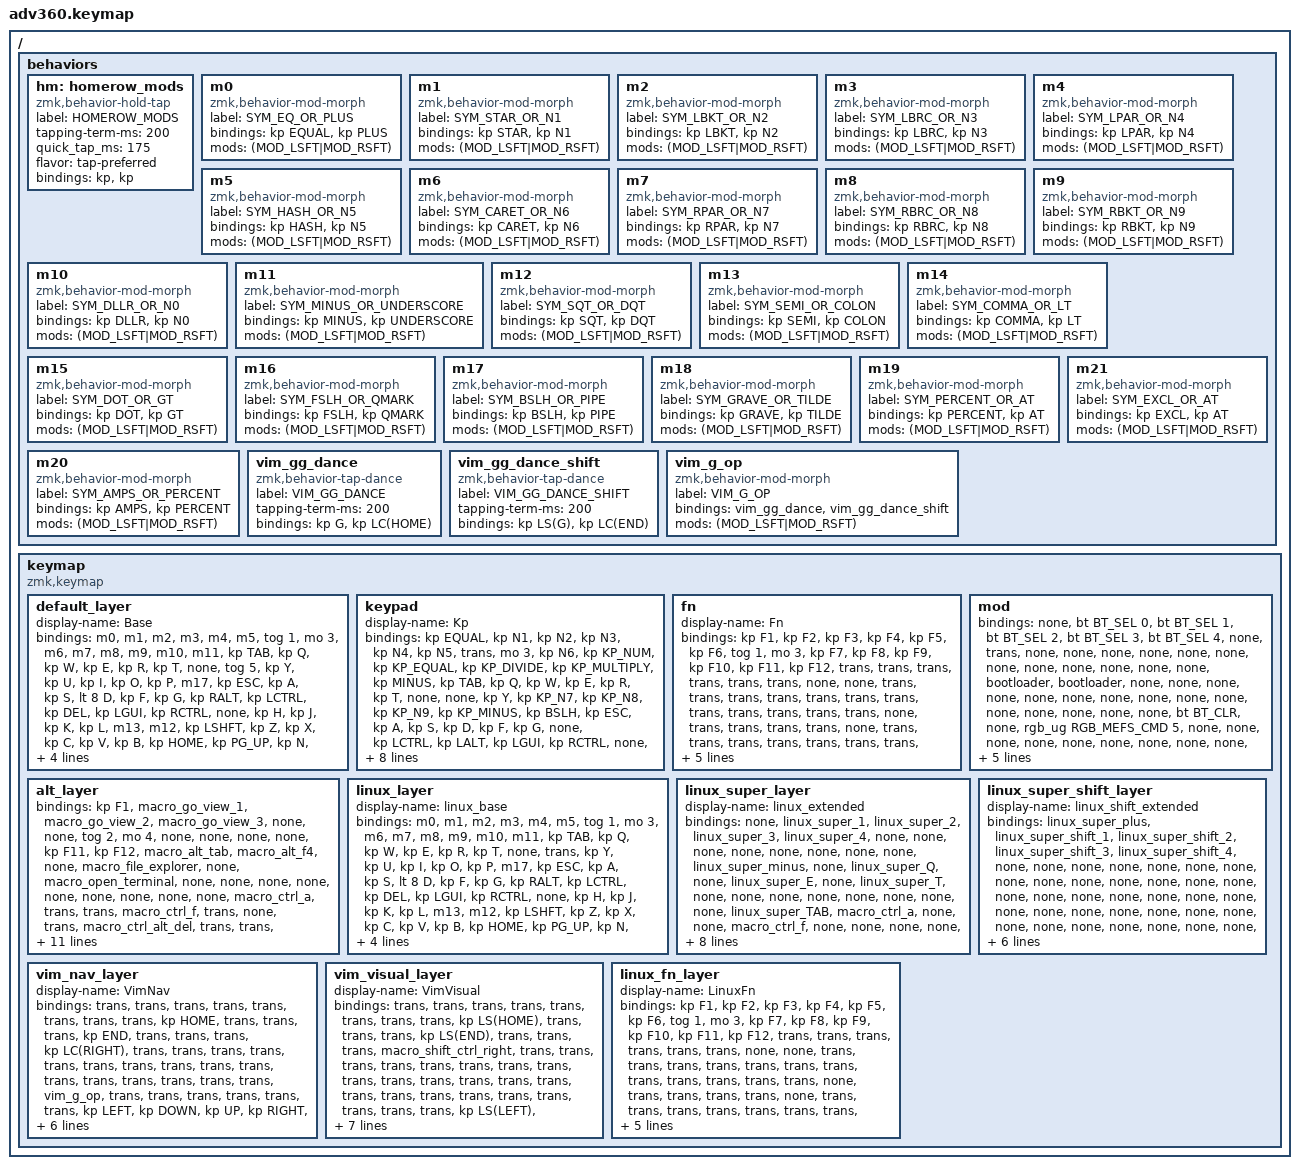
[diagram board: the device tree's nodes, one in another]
#include <behaviors.dtsi>
#include <dt-bindings/zmk/keys.h>
#include <dt-bindings/zmk/bt.h>
#include <dt-bindings/zmk/rgb.h>
#include <dt-bindings/zmk/stp.h>
#include <dt-bindings/zmk/backlight.h>
#include <dt-bindings/zmk/pointing.h>

/ {
    behaviors {
      #include "macros.dtsi"
      #include "version.dtsi"

      hm: homerow_mods {
          compatible = "zmk,behavior-hold-tap";
          label = "HOMEROW_MODS";
          #binding-cells = <2>;
          tapping-term-ms = <200>;
          quick_tap_ms = <175>;
          flavor = "tap-preferred";
          bindings = <&kp>, <&kp>;
      };

      m0: m0 {
          compatible = "zmk,behavior-mod-morph";
          label = "SYM_EQ_OR_PLUS";
          #binding-cells = <0>;
          bindings = <&kp EQUAL>, <&kp PLUS>;  // = <> +
          mods = <(MOD_LSFT|MOD_RSFT)>;
      };

      m1: m1 {
          compatible = "zmk,behavior-mod-morph";
          label = "SYM_STAR_OR_N1";
          #binding-cells = <0>;
          bindings = <&kp STAR>, <&kp N1>; // * <> 1
          mods = <(MOD_LSFT|MOD_RSFT)>;
      };

      m2: m2 {
          compatible = "zmk,behavior-mod-morph";
          label = "SYM_LBKT_OR_N2";
          #binding-cells = <0>;
          bindings = <&kp LBKT>, <&kp N2>; // [ <> 2
          mods = <(MOD_LSFT|MOD_RSFT)>;
      };

      m3: m3 {
          compatible = "zmk,behavior-mod-morph";
          label = "SYM_LBRC_OR_N3";
          #binding-cells = <0>;
          bindings = <&kp LBRC>, <&kp N3>; // { <> 3
          mods = <(MOD_LSFT|MOD_RSFT)>;
      };

      m4: m4 {
          compatible = "zmk,behavior-mod-morph";
          label = "SYM_LPAR_OR_N4";
          #binding-cells = <0>;
          bindings = <&kp LPAR>, <&kp N4>; // ( <> 4
          mods = <(MOD_LSFT|MOD_RSFT)>;
      };

      m5: m5 {
          compatible = "zmk,behavior-mod-morph";
          label = "SYM_HASH_OR_N5";
          #binding-cells = <0>;
          bindings = <&kp HASH>, <&kp N5>; // # <> 5
          mods = <(MOD_LSFT|MOD_RSFT)>;
      };

      m6: m6 {
          compatible = "zmk,behavior-mod-morph";
          label = "SYM_CARET_OR_N6";
          #binding-cells = <0>;
          bindings = <&kp CARET>, <&kp N6>; // ^ <> 6
          mods = <(MOD_LSFT|MOD_RSFT)>;
      };

      m7: m7 {
          compatible = "zmk,behavior-mod-morph";
          label = "SYM_RPAR_OR_N7";
          #binding-cells = <0>;
          bindings = <&kp RPAR>, <&kp N7>; // ) <> 7
          mods = <(MOD_LSFT|MOD_RSFT)>;
      };

      m8: m8 {
          compatible = "zmk,behavior-mod-morph";
          label = "SYM_RBRC_OR_N8";
          #binding-cells = <0>;
          bindings = <&kp RBRC>, <&kp N8>; // } <> 8
          mods = <(MOD_LSFT|MOD_RSFT)>;
      };

      m9: m9 {
          compatible = "zmk,behavior-mod-morph";
          label = "SYM_RBKT_OR_N9";
          #binding-cells = <0>;
          bindings = <&kp RBKT>, <&kp N9>; // ] <> 9
          mods = <(MOD_LSFT|MOD_RSFT)>;
      };

      m10: m10 {
          compatible = "zmk,behavior-mod-morph";
          label = "SYM_DLLR_OR_N0";
          #binding-cells = <0>;
          bindings = <&kp DLLR>, <&kp N0>; // $ <> 0
          mods = <(MOD_LSFT|MOD_RSFT)>;
      };

      m11: m11 {
          compatible = "zmk,behavior-mod-morph";
          label = "SYM_MINUS_OR_UNDERSCORE"; // - <> _
          #binding-cells = <0>;
          bindings = <&kp MINUS>, <&kp UNDERSCORE>;
          mods = <(MOD_LSFT|MOD_RSFT)>;
      };

      m12: m12 {
          compatible = "zmk,behavior-mod-morph";
          label = "SYM_SQT_OR_DQT"; // ' <> "
          #binding-cells = <0>;
          bindings = <&kp SQT>, <&kp DQT>;
          mods = <(MOD_LSFT|MOD_RSFT)>;
      };

      m13: m13 {
          compatible = "zmk,behavior-mod-morph";
          label = "SYM_SEMI_OR_COLON"; // ; <> :
          #binding-cells = <0>;
          bindings = <&kp SEMI>, <&kp COLON>;
          mods = <(MOD_LSFT|MOD_RSFT)>;
      };

      m14: m14 {
          compatible = "zmk,behavior-mod-morph";
          label = "SYM_COMMA_OR_LT"; // , <> <
              #binding-cells = <0>;
              bindings = <&kp COMMA>, <&kp LT>;
              mods = <(MOD_LSFT|MOD_RSFT)>;
      };

      m15: m15 {
          compatible = "zmk,behavior-mod-morph";
          label = "SYM_DOT_OR_GT"; // . <> >
          #binding-cells = <0>;
          bindings = <&kp DOT>, <&kp GT>;
          mods = <(MOD_LSFT|MOD_RSFT)>;
      };

      m16: m16 {
          compatible = "zmk,behavior-mod-morph";
          label = "SYM_FSLH_OR_QMARK"; // / <> ?
          #binding-cells = <0>;
          bindings = <&kp FSLH>, <&kp QMARK>;
          mods = <(MOD_LSFT|MOD_RSFT)>;
      };

      m17: m17 {
          compatible = "zmk,behavior-mod-morph";
          label = "SYM_BSLH_OR_PIPE"; // \ <> |
          #binding-cells = <0>;
          bindings = <&kp BSLH>, <&kp PIPE>;
          mods = <(MOD_LSFT|MOD_RSFT)>;
      };

      m18: m18 {
          compatible = "zmk,behavior-mod-morph";
          label = "SYM_GRAVE_OR_TILDE"; // ` <> ~
          #binding-cells = <0>;
          bindings = <&kp GRAVE>, <&kp TILDE>;
          mods = <(MOD_LSFT|MOD_RSFT)>;
      };

      m19: m19 {
          compatible = "zmk,behavior-mod-morph";
          label = "SYM_PERCENT_OR_AT"; // % <> @
          #binding-cells = <0>;
          bindings = <&kp PERCENT>, <&kp AT>;
          mods = <(MOD_LSFT|MOD_RSFT)>;
      };

      m20: m20 {
          compatible = "zmk,behavior-mod-morph";
          label = "SYM_AMPS_OR_PERCENT"; // & <> %
          #binding-cells = <0>;
          bindings = <&kp AMPS>, <&kp PERCENT>;
          mods = <(MOD_LSFT|MOD_RSFT)>;
      };

      m21: m21 {
          compatible = "zmk,behavior-mod-morph";
          label = "SYM_EXCL_OR_AT"; // ! <> @
          #binding-cells = <0>;
          bindings = <&kp EXCL>, <&kp AT>;
          mods = <(MOD_LSFT|MOD_RSFT)>;
      };

      // G while D is held (see vim_nav_layer): double-tap g (unshifted) jumps to the top
      // of the page/doc (Ctrl+Home, vim "gg"); double-tap G (shift held) jumps to the
      // bottom (Ctrl+End, vim "G"). A single tap either way just falls through to g/G.
      vim_gg_dance: vim_gg_dance {
          compatible = "zmk,behavior-tap-dance";
          label = "VIM_GG_DANCE";
          #binding-cells = <0>;
          tapping-term-ms = <200>;
          bindings = <&kp G>, <&kp LC(HOME)>;
      };

      vim_gg_dance_shift: vim_gg_dance_shift {
          compatible = "zmk,behavior-tap-dance";
          label = "VIM_GG_DANCE_SHIFT";
          #binding-cells = <0>;
          tapping-term-ms = <200>;
          bindings = <&kp LS(G)>, <&kp LC(END)>;
      };

      vim_g_op: vim_g_op {
          compatible = "zmk,behavior-mod-morph";
          label = "VIM_G_OP";
          #binding-cells = <0>;
          bindings = <&vim_gg_dance>, <&vim_gg_dance_shift>;
          mods = <(MOD_LSFT|MOD_RSFT)>;
      };

    };



    keymap {
        compatible = "zmk,keymap";



    // 0 - Windows compatible
    default_layer {
                display-name = "Base";
                bindings = <

                    &m0     &m1     &m2     &m3     &m4     &m5     &tog 1                                                  &mo 3     &m6     &m7     &m8     &m9     &m10    &m11
                    &kp TAB  &kp Q   &kp W   &kp E   &kp R   &kp T   &none                                                  &tog 5     &kp Y   &kp U   &kp I   &kp O   &kp P   &m17
                    &kp ESC  &kp A   &kp S   &lt 8 D   &kp F   &kp G   &kp RALT        &kp LCTRL &kp DEL  &kp LGUI &kp RCTRL       &none    &kp H   &kp J   &kp K   &kp L   &m13    &m12
                    &kp LSHFT    &kp Z   &kp X   &kp C   &kp V   &kp B                          &kp HOME  &kp PG_UP                    &kp N   &kp M   &m14    &m15    &m16   &kp RSHFT 
                    &mo 2    &m18    &m19    &kp LEFT &kp RIGHT          &kp BSPC &mo 4    &kp END  &kp PG_DN &kp ENTER  &kp SPACE          &kp DOWN &kp UP  &m20    &m21    &mo 2


                >;
            };


     // 1
    keypad {
        display-name = "Kp";
        bindings = <
            &kp EQUAL &kp N1    &kp N2   &kp N3   &kp N4     &kp N5 &trans                                                           &mo 3 &kp N6 &kp KP_NUM &kp KP_EQUAL &kp KP_DIVIDE &kp KP_MULTIPLY &kp MINUS
            &kp TAB   &kp Q     &kp W    &kp E    &kp R      &kp T  &none                                                            &none &kp Y  &kp KP_N7  &kp KP_N8    &kp KP_N9     &kp KP_MINUS    &kp BSLH
            &kp ESC   &kp A     &kp S    &kp D    &kp F      &kp G  &none           &kp LCTRL &kp LALT &kp LGUI  &kp RCTRL           &none &kp H  &kp KP_N4  &kp KP_N5    &kp KP_N6     &kp KP_PLUS     &kp SQT
            &kp LSHFT &kp Z     &kp X    &kp C    &kp V      &kp B                            &kp HOME &kp PG_UP                           &kp N  &kp KP_N1  &kp KP_N2    &kp KP_N3     &kp KP_ENTER    &kp RSHFT
            &mo 2     &kp GRAVE &kp CAPS &kp LEFT &kp RIGHT                &kp BSPC &kp DEL   &kp END  &kp PG_DN &kp ENTER &kp KP_N0              &kp UP     &kp DOWN     &kp KP_DOT    &kp RBKT        &mo 2
        >;
    };


     // 2
    fn {
        display-name = "Fn";
        bindings = <
            &kp F1 &kp F2 &kp F3 &kp F4 &kp F5 &kp F6 &tog 1                                           &mo 3 &kp F7 &kp F8 &kp F9 &kp F10 &kp F11 &kp F12
            &trans &trans &trans &trans &trans &trans  &none                                           &none &trans &trans &trans &trans  &trans  &trans
            &trans &trans &trans &trans &trans &trans  &none        &trans &trans &trans &trans        &none &trans &trans &trans &trans  &trans  &trans
            &trans &trans &trans &trans &trans &trans                      &trans &trans                     &trans &trans &trans &trans  &trans  &trans
            &trans &trans &trans &trans &trans               &trans &trans &trans &trans &trans &trans              &trans &trans &trans  &trans  &trans
        >;
    };



    // 3
    mod {
          bindings = <
            &none &bt BT_SEL 0 &bt BT_SEL 1 &bt BT_SEL 2 &bt BT_SEL 3 &bt BT_SEL 4 &none                                                                     &trans                 &none        &none        &none        &none &none &none
            &none &none        &none        &none        &none        &none        &bootloader                                                               &bootloader            &none        &none        &none        &none &none &none
            &none &none        &none        &none        &none        &none        &none                   &none &none &bt BT_CLR &none                      &rgb_ug RGB_MEFS_CMD 5 &none        &none        &none        &none &none &none
            &none &none        &none        &none        &macro_ver   &none                                      &none &none                                                        &none        &none        &none        &none &none &none
            &none &none        &none        &none        &none                                       &none &none &none &none      &bl BL_TOG &rgb_ug RGB_TOG                                     &bl BL_INC   &bl BL_DEC   &none &none &none
          >;
        };

        // 4
        alt_layer {
            bindings = <
                &kp F1 &macro_go_view_1 &macro_go_view_2 &macro_go_view_3 &none &none &tog 2                                           &mo 4 &none &none &none &none &kp F11 &kp F12
                &macro_alt_tab &macro_alt_f4 &none &macro_file_explorer &none &macro_open_terminal &none                                           &none &none &none &none &none  &none  &none
                &none &macro_ctrl_a &trans &trans &macro_ctrl_f &trans  &none        &trans &macro_ctrl_alt_del &trans &trans        &none &macro_left_screen &macro_min_screen &macro_max_screen &macro_right_screen  &trans  &trans
                &trans &macro_ctrl_z &macro_ctrl_x &macro_ctrl_c &macro_ctrl_v &trans                      &trans &trans                     &trans &trans &trans &trans  &trans  &trans
                &trans &trans &trans &macro_shift_ctrl_left &macro_shift_ctrl_right               &macro_ctrl_backspace &trans &trans &trans &trans &trans              &macro_shift_down &macro_shift_up &trans  &trans  &trans
            >;
        };

    // 5
    linux_layer {
                display-name = "linux_base";
                bindings = <

                    &m0     &m1     &m2     &m3     &m4     &m5     &tog 1                                                  &mo 3     &m6     &m7     &m8     &m9     &m10    &m11
                    &kp TAB  &kp Q   &kp W   &kp E   &kp R   &kp T   &none                                                  &trans     &kp Y   &kp U   &kp I   &kp O   &kp P   &m17
                    &kp ESC  &kp A   &kp S   &lt 8 D   &kp F   &kp G   &kp RALT        &kp LCTRL &kp DEL  &kp LGUI &kp RCTRL       &none    &kp H   &kp J   &kp K   &kp L   &m13    &m12
                    &kp LSHFT    &kp Z   &kp X   &kp C   &kp V   &kp B                          &kp HOME  &kp PG_UP                    &kp N   &kp M   &m14    &m15    &m16   &kp RSHFT 
                    &mo 10    &m18    &m19    &kp LEFT &kp RIGHT          &kp BSPC &mo 6 &kp END  &kp PG_DN &kp ENTER  &kp SPACE          &kp DOWN &kp UP  &m20    &m21    &mo 10


                >;
            };

    // 6
    linux_super_layer {
        display-name = "linux_extended";
        bindings = <
            &none &linux_super_1 &linux_super_2 &linux_super_3 &linux_super_4 &none  &none                                           &none &none &none &none &none  &none  &linux_super_minus
            &none &linux_super_Q &none &linux_super_E &none &linux_super_T  &none                                           &none &none &none &none &none  &none  &none
            &linux_super_TAB &macro_ctrl_a &none &none &macro_ctrl_f &none  &none        &none &none &none &none        &none &linux_super_H &linux_super_J &linux_super_K &linux_super_L  &none  &none
            &mo 7 &macro_ctrl_z &macro_ctrl_x &macro_ctrl_c &macro_ctrl_v &none                      &none &none                     &none &none &none &none  &none  &mo 7
            &none &none &none &none &none               &macro_ctrl_backspace &none &none &none &none &none              &none &none &none  &none  &none
        >;
    };


    // 7
    linux_super_shift_layer {
        display-name = "linux_shift_extended";
        bindings = <
            &linux_super_plus &linux_super_shift_1 &linux_super_shift_2 &linux_super_shift_3 &linux_super_shift_4 &none  &none                                           &none &none &none &none &none  &none  &none
            &none &none &none &none &none &none  &none                                           &none &none &none &none &none  &none  &none
            &none &none &none &none &none &none  &none        &none &none &none &none        &none &none &none &none &none  &none  &none
            &none &none &none &none &none &none                      &none &none                     &none &none &none &none  &none  &none
            &none &none &none &none &none               &none &none &none &none &none &none              &none &none &none  &none  &none
        >;
    };




    // 8 - held from the D key on default_layer/linux_layer (tap D = "d", hold D = vim nav;
    // hold V too -> vim_visual_layer, vim visual-mode selection)
    vim_nav_layer {
        display-name = "VimNav";
        bindings = <
            &trans &trans &trans &trans &trans &trans &trans                                                  &trans &kp HOME &trans &trans &trans &kp END &trans
            &trans &trans &kp LC(RIGHT) &trans &trans &trans &trans                                                  &trans &trans &trans &trans &trans &trans &trans
            &trans &trans &trans &trans &trans &vim_g_op &trans        &trans &trans &trans &trans        &trans &kp LEFT &kp DOWN &kp UP &kp RIGHT &trans &trans
            &trans &trans &trans &trans &lt 9 V &kp LC(LEFT)                      &trans &trans                     &trans &trans &trans &trans &trans &trans
            &trans &trans &trans &trans &trans               &trans &trans &trans &trans &trans &trans              &trans &trans &trans &trans &trans
        >;
    };

    // 9 - held from V while D is held (D -> hold V -> hjkl/w/e/b/$/& = vim visual mode: select)
    vim_visual_layer {
        display-name = "VimVisual";
        bindings = <
            &trans &trans &trans &trans &trans &trans &trans                                                  &trans &kp LS(HOME) &trans &trans &trans &kp LS(END) &trans
            &trans &trans &macro_shift_ctrl_right &trans &trans &trans &trans                                                  &trans &trans &trans &trans &trans &trans &trans
            &trans &trans &trans &trans &trans &trans &trans        &trans &trans &trans &trans        &trans &kp LS(LEFT) &kp LS(DOWN) &kp LS(UP) &kp LS(RIGHT) &trans &trans
            &trans &trans &trans &trans &trans &macro_shift_ctrl_left                      &trans &trans                     &trans &trans &trans &trans &trans &trans
            &trans &trans &trans &trans &trans               &trans &trans &trans &trans &trans &trans              &trans &trans &trans &trans &trans
        >;
    };

    // 10 - held from linux_layer's Fn key (see &mo 10 above). Same F1-F12 layout as the
    // shared fn layer (2), just numbered above linux_layer (5) so it isn't shadowed by it.
    linux_fn_layer {
        display-name = "LinuxFn";
        bindings = <
            &kp F1 &kp F2 &kp F3 &kp F4 &kp F5 &kp F6 &tog 1                                           &mo 3 &kp F7 &kp F8 &kp F9 &kp F10 &kp F11 &kp F12
            &trans &trans &trans &trans &trans &trans  &none                                           &none &trans &trans &trans &trans  &trans  &trans
            &trans &trans &trans &trans &trans &trans  &none        &trans &trans &trans &trans        &none &trans &trans &trans &trans  &trans  &trans
            &trans &trans &trans &trans &trans &trans                      &trans &trans                     &trans &trans &trans &trans  &trans  &trans
            &trans &trans &trans &trans &trans               &trans &trans &trans &trans &trans &trans              &trans &trans &trans  &trans  &trans
        >;
    };
  };
};
